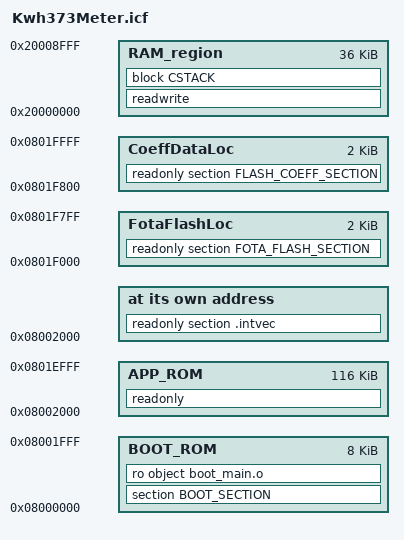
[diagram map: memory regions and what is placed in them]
/*###ICF### Section handled by ICF editor, don't touch! ****/
/*-Editor annotation file-*/
/* IcfEditorFile="$TOOLKIT_DIR$\config\ide\IcfEditor\cortex_v1_0.xml" */
/*-Specials-*/
define symbol __ICFEDIT_intvec_start__ = 0x08002000;
/*-Memory Regions-*/
define symbol __ICFEDIT_region_ROM_start__ = 0x08002000;
define symbol __ICFEDIT_region_ROM_end__   = 0x0801EFff;
define symbol __ICFEDIT_region_RAM_start__ = 0x20000000;
define symbol __ICFEDIT_region_RAM_end__   = 0x20008FFF;
/*-Sizes-*/
define symbol __ICFEDIT_size_cstack__ = 0x2000;
/**** End of ICF editor section. ###ICF###*/

define memory mem with size = 4G;

/* Bootloader: pages 0-3 (8KB). Not updated by FOTA.
   NOTE: The bootloader currently fits in ~1.7 KB, so this region can be
   reduced to pages 0-1 (4KB, 0x08000000-0x08000FFF) to reclaim 4 KB for
   the application. If you do this, also update BOOT_FLASH_SIZE and
   BOOT_APP_ADDRESS in boot_defs.h, BOOTLOADER_SIZE in fota_pack.py, and
   APP_ROM start below. Re-flashing the smaller bootloader requires SWD
   since the bootloader cannot self-update via FOTA. */
define region BOOT_ROM     = mem:[from 0x08000000 to 0x08001FFF];

/* Application: pages 4-61 */
define region APP_ROM      = mem:[from __ICFEDIT_region_ROM_start__ to __ICFEDIT_region_ROM_end__];

/* FOTA upgrade metadata: page 62 */
define region FotaFlashLoc = mem:[from 0x0801F000 to 0x0801F7FF];

/* Calibration coefficients: page 63 */
define region CoeffDataLoc = mem:[from 0x0801F800 to 0x0801FFFF];

define region RAM_region   = mem:[from __ICFEDIT_region_RAM_start__ to __ICFEDIT_region_RAM_end__];

define block CSTACK    with alignment = 8, size = __ICFEDIT_size_cstack__   { };

initialize by copy { readwrite };
do not initialize  { section .noinit };

/* Bootloader: boot_vectors.s places .boot_intvec at absolute 0x08000000
   via ASEGN (no linker placement needed for it).
   BOOT_SECTION (reset handler from .s) and all of boot_main.o go here.

   The bootloader is not referenced by the application's entry point
   (__iar_program_start), so without `keep` the linker strips .boot_intvec
   (declared NOROOT in boot_vectors.s) and its dependency chain — leaving
   BOOT_ROM empty and no Reset_Handler at 0x08000000.
   Keeping .boot_intvec transitively keeps Boot_Reset_Handler
   (BOOT_SECTION) and Boot_ResetHandler (boot_main.o) via call refs. */
keep { section .boot_intvec };
place in BOOT_ROM  { section BOOT_SECTION,
                     ro object boot_main.o };

/* Application vector table at 0x08002000 */
place at address mem:__ICFEDIT_intvec_start__ { readonly section .intvec };

/* Flash-resident data sections */
place in FotaFlashLoc {readonly section FOTA_FLASH_SECTION};
place in CoeffDataLoc {readonly section FLASH_COEFF_SECTION};

/* Application code and constants */
place in APP_ROM   { readonly };
place in RAM_region { readwrite,
                      block CSTACK };
